# CY8C5888AXI_LP096 register map
File version: 0.1
Registers are 8-bit, read-write, no defined reset value unless marked. A register's access mark holds for its fields unless they carry their own. Offsets are from the block's base; [hi:lo] are bit positions; 'fields as' and 'values as' point back to an identical list.

## UART_MODX_2 — UART
Base 0x00000000
0x40006428 RX_UART_MODX_2_RX_ADDRESS1 — RX Address1 Register
0x40006438 RX_UART_MODX_2_RX_ADDRESS2 — RX Address2 Register
0x40006445 TX_UART_MODX_2_TX_DATA — TX Data Register
0x40006448 RX_UART_MODX_2_RX_DATA — RX Data Register
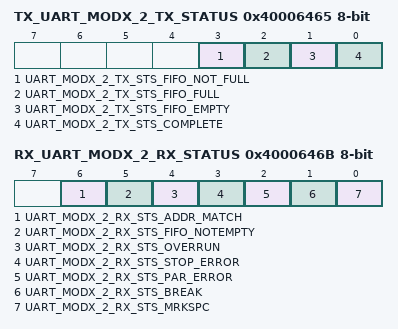
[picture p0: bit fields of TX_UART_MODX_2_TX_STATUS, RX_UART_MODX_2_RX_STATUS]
0x40006465 TX_UART_MODX_2_TX_STATUS — TX status register
  [3] UART_MODX_2_TX_STS_FIFO_NOT_FULL ro, [2] UART_MODX_2_TX_STS_FIFO_FULL ro, [1] UART_MODX_2_TX_STS_FIFO_EMPTY ro, [0] UART_MODX_2_TX_STS_COMPLETE ro
0x4000646B RX_UART_MODX_2_RX_STATUS — RX status register
  [6] UART_MODX_2_RX_STS_ADDR_MATCH ro, [5] UART_MODX_2_RX_STS_FIFO_NOTEMPTY ro, [4] UART_MODX_2_RX_STS_OVERRUN ro, [3] UART_MODX_2_RX_STS_STOP_ERROR ro, [2] UART_MODX_2_RX_STS_PAR_ERROR ro, [1] UART_MODX_2_RX_STS_BREAK ro, [0] UART_MODX_2_RX_STS_MRKSPC ro

## UART_MODX_1 — UART
Base 0x00000000
0x40006446 TX_UART_MODX_1_TX_DATA — TX Data Register
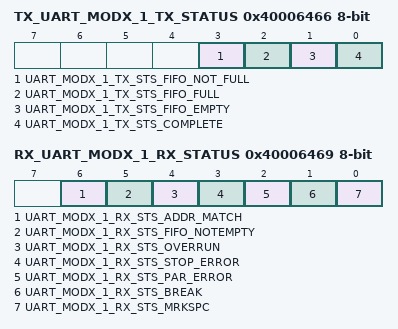
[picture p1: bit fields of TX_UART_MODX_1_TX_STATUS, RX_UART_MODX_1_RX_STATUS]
0x40006466 TX_UART_MODX_1_TX_STATUS — TX status register
  [3] UART_MODX_1_TX_STS_FIFO_NOT_FULL ro, [2] UART_MODX_1_TX_STS_FIFO_FULL ro, [1] UART_MODX_1_TX_STS_FIFO_EMPTY ro, [0] UART_MODX_1_TX_STS_COMPLETE ro
0x40006469 RX_UART_MODX_1_RX_STATUS — RX status register
  [6] UART_MODX_1_RX_STS_ADDR_MATCH ro, [5] UART_MODX_1_RX_STS_FIFO_NOTEMPTY ro, [4] UART_MODX_1_RX_STS_OVERRUN ro, [3] UART_MODX_1_RX_STS_STOP_ERROR ro, [2] UART_MODX_1_RX_STS_PAR_ERROR ro, [1] UART_MODX_1_RX_STS_BREAK ro, [0] UART_MODX_1_RX_STS_MRKSPC ro
0x40006529 RX_UART_MODX_1_RX_ADDRESS1 — RX Address1 Register
0x40006539 RX_UART_MODX_1_RX_ADDRESS2 — RX Address2 Register
0x40006549 RX_UART_MODX_1_RX_DATA — RX Data Register

## UART_STIM_1 — UART
Base 0x00000000
0x4000644C TX_UART_STIM_1_TX_DATA — TX Data Register
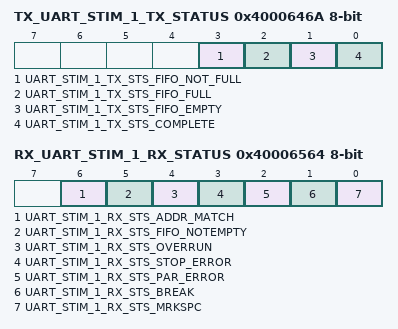
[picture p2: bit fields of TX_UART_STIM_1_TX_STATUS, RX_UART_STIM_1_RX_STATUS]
0x4000646A TX_UART_STIM_1_TX_STATUS — TX status register
  [3] UART_STIM_1_TX_STS_FIFO_NOT_FULL ro, [2] UART_STIM_1_TX_STS_FIFO_FULL ro, [1] UART_STIM_1_TX_STS_FIFO_EMPTY ro, [0] UART_STIM_1_TX_STS_COMPLETE ro
0x40006527 RX_UART_STIM_1_RX_ADDRESS1 — RX Address1 Register
0x40006537 RX_UART_STIM_1_RX_ADDRESS2 — RX Address2 Register
0x40006547 RX_UART_STIM_1_RX_DATA — RX Data Register
0x40006564 RX_UART_STIM_1_RX_STATUS — RX status register
  [6] UART_STIM_1_RX_STS_ADDR_MATCH ro, [5] UART_STIM_1_RX_STS_FIFO_NOTEMPTY ro, [4] UART_STIM_1_RX_STS_OVERRUN ro, [3] UART_STIM_1_RX_STS_STOP_ERROR ro, [2] UART_STIM_1_RX_STS_PAR_ERROR ro, [1] UART_STIM_1_RX_STS_BREAK ro, [0] UART_STIM_1_RX_STS_MRKSPC ro

## UART_STIM_0 — UART
Base 0x00000000
0x4000642F RX_UART_STIM_0_RX_ADDRESS1 — RX Address1 Register
0x4000643F RX_UART_STIM_0_RX_ADDRESS2 — RX Address2 Register
0x40006444 TX_UART_STIM_0_TX_DATA — TX Data Register
0x4000644F RX_UART_STIM_0_RX_DATA — RX Data Register
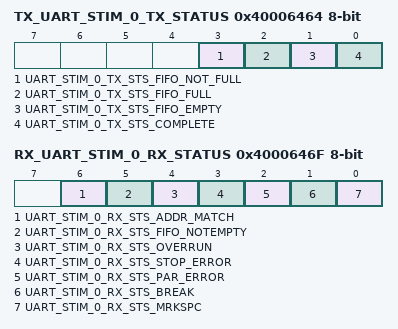
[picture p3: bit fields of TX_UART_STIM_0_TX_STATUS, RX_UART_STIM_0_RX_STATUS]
0x40006464 TX_UART_STIM_0_TX_STATUS — TX status register
  [3] UART_STIM_0_TX_STS_FIFO_NOT_FULL ro, [2] UART_STIM_0_TX_STS_FIFO_FULL ro, [1] UART_STIM_0_TX_STS_FIFO_EMPTY ro, [0] UART_STIM_0_TX_STS_COMPLETE ro
0x4000646F RX_UART_STIM_0_RX_STATUS — RX status register
  [6] UART_STIM_0_RX_STS_ADDR_MATCH ro, [5] UART_STIM_0_RX_STS_FIFO_NOTEMPTY ro, [4] UART_STIM_0_RX_STS_OVERRUN ro, [3] UART_STIM_0_RX_STS_STOP_ERROR ro, [2] UART_STIM_0_RX_STS_PAR_ERROR ro, [1] UART_STIM_0_RX_STS_BREAK ro, [0] UART_STIM_0_RX_STS_MRKSPC ro

## PWM_1
Base 0x00000000
0x4000642A PWM_1_COMPARE_Reg_ — UDB.D0 - Assigned Compare Value
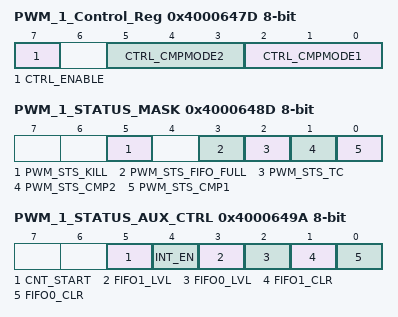
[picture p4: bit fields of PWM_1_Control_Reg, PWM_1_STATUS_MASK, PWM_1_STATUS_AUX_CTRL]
0x4000647D PWM_1_Control_Reg — UDB Control Register - Assigned Control Register Value
  [7] CTRL_ENABLE — Enable the PWM
  [5:3] CTRL_CMPMODE2 — Compare mode 2
  [2:0] CTRL_CMPMODE1 — Compare mode 1
0x4000648D PWM_1_STATUS_MASK — UDB Status bits Interrupt Mask Enable Register
  [5] PWM_STS_KILL ro — Enables the Interrupt on Kill
  [3] PWM_STS_FIFO_FULL ro — FIFO Full Status Mask
  [2] PWM_STS_TC ro — Enables the Interrupt on Terminal Count
  [1] PWM_STS_CMP2 ro — Enables the Interrupt on Compare 2
  [0] PWM_STS_CMP1 ro — Enables the Interrupt on Compare 1
0x4000649A PWM_1_STATUS_AUX_CTRL — UDB Auxilliary Control Register
  [5] CNT_START — FIFO0 clear
    0=E_CNT_START0 (Disable counter); 1=E_CNT_START1 (Enable counter)
  [4] INT_EN
    0=E_INT_EN0 (Interrupt disabled); 1=E_INT_EN1 (Interrupt enabled)
  [3] FIFO1_LVL — FIFO level
    0=E_FIFO_LVL_0 (FIFO LVL: input mode: FIFO not full; output mode: FIFO not empty); 1=E_FIFO_LVL_1 (FIFO LVL: input mode: FIFO at least 1/2 empty; output mode: FIFO at least 1/2 full)
  [2] FIFO0_LVL — FIFO level
    values as FIFO1_LVL
  [1] FIFO1_CLR — FIFO1 clear
    0=E_FIFO_CLR_0 (Normal FIFO operation); 1=E_FIFO_CLR_1 (Clear FIFO state)
  [0] FIFO0_CLR — FIFO0 clear
    values as FIFO1_CLR
